# STM32WL5X_CM4 register map
File version: 2.2
CPU: CM4 r0p1, little endian, MPU, no FPU, 4 interrupt priority bits
Registers are 32-bit, read-write, reset 0x0 unless marked. A register's access mark holds for its fields unless they carry their own. Offsets are from the block's base; [hi:lo] are bit positions; {n}, {i} and the like mark numbered series; 'fields as' and 'values as' point back to an identical list.

## IPCC — Inter Processor communication controller
Base 0x58000C00
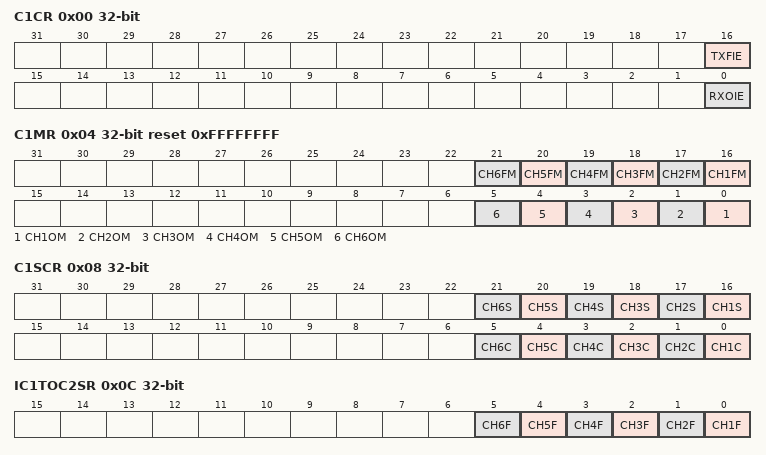
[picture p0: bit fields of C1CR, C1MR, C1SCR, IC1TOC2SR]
0x00 C1CR — IPCC Processor 1 control register
  [16] TXFIE
    0=Disabled (Processor TX free interrupt disabled); 1=Enabled (Enable an unmasked processor transmit channel free to generate a TX free interrupt)
  [0] RXOIE
    0=Disabled (Processor RX occupied interrupt disabled); 1=Enabled (Enable an unmasked processor receive channel occupied to generate an RX occupied interrupt)
0x04 C1MR reset 0xFFFFFFFF — IPCC Processor 1 mask register
  [n+15] CH{n}FM (n=1..6)
    0=Unmasked (Transmit channel n free interrupt not masked); 1=Masked (Transmit channel n free interrupt masked)
  [n-1] CH{n}OM (n=1..6)
    0=Unmasked (Receive channel n occupied interrupt not masked); 1=Masked (Receive channel n occupied interrupt masked)
0x08 C1SCR — Reading this register will always return 0x0000 0000.
  [n+15] CH{n}S (n=1..6)
    0=NoAction; 1=Set (Processor transmit channel n status bit set)
  [n-1] CH{n}C (n=1..6)
    0=NoAction; 1=Clear (Processor receive channel n status bit clear)
0x0C IC1TOC2SR ro — IPCC processor 1 to processor 2 status register
  [n-1] CH{n}F (n=1..6)
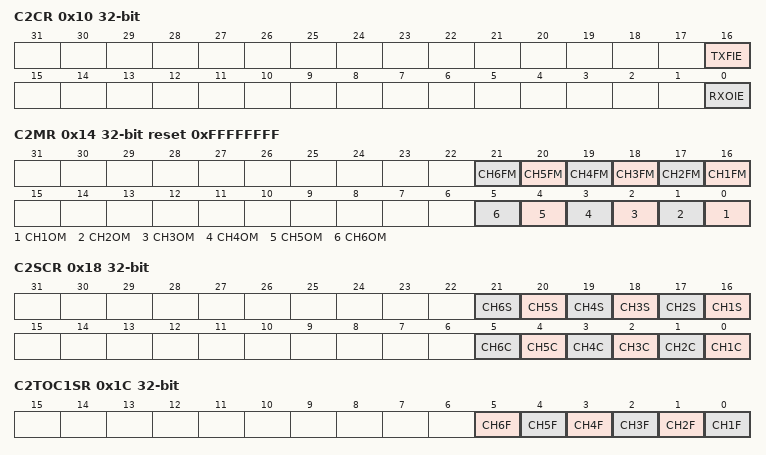
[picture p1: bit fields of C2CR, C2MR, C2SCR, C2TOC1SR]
0x10 C2CR — IPCC Processor 2 control register
  fields as C1CR
0x14 C2MR reset 0xFFFFFFFF — IPCC Processor 2 mask register
  fields as C1MR
0x18 C2SCR — Reading this register will always return 0x0000 0000.
  fields as C1SCR
0x1C C2TOC1SR ro — IPCC processor 2 to processor 1 status register
  [5] CH6F
  [n-1] CH{n}F (n=1..5)
    0=Free (Channel free, data can be written by the sending processor. Generates a channel TX free interrupt to the current processor, when unmasked); 1=Occupied (Channel occupied, data can be read by the receiving processor. Generates a channel RX occupied interrupt to the other processor, when unmasked)
0x3F0 HWCFGR ro reset 0x6 — IPCC Hardware configuration register
  [7:0] CHANNELS
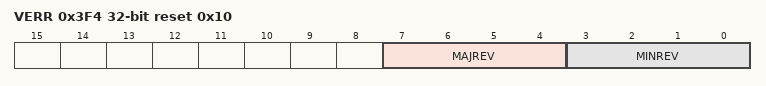
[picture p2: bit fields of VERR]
0x3F4 VERR ro reset 0x10 — IPCC IP Version register
  [7:4] MAJREV, [3:0] MINREV
0x3F8 IPIDR ro reset 0x100071 — IPCC IP Identification register
  [31:0] ID
0x3FC SIDR ro reset 0xA3C5DD01 — IPCC Size ID register
  [31:0] SID

## IWDG — Independent watchdog
Base 0x40003000
0x00 KR 16-bit wo — Key register
  [15:0] KEY — Key value (write only, read 0x0000)
    0x5555=Unlock (Enable access to PR, RLR and WINR registers); 0xAAAA=Feed watchdog with RLR register value; 0xCCCC=Start the watchdog
0x04 PR 16-bit reset 0x7 — Prescaler register
  [2:0] PR — Prescaler divider
    0=DivideBy4 (Divider /4); 1=DivideBy8 (Divider /8); 2=DivideBy16 (Divider /16); 3=DivideBy32 (Divider /32); 4=DivideBy64 (Divider /64); 5=DivideBy128 (Divider /128); other=DivideBy256 (Divider /256)
0x08 RLR 16-bit reset 0xFFF — Reload register
  [11:0] RL — Watchdog counter reload value
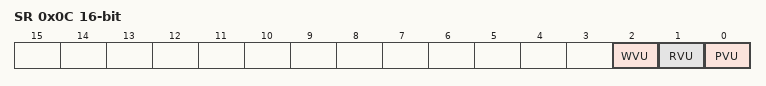
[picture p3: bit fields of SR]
0x0C SR 16-bit ro — Status register
  [all] fields
    0=Idle (No update on-going); 1=Busy (Update on-going)
  [2] WVU — Watchdog counter window value update
  [1] RVU — Watchdog counter reload value update
  [0] PVU — Watchdog prescaler value update

## PKA — Public key accelerator
Base 0x58002000
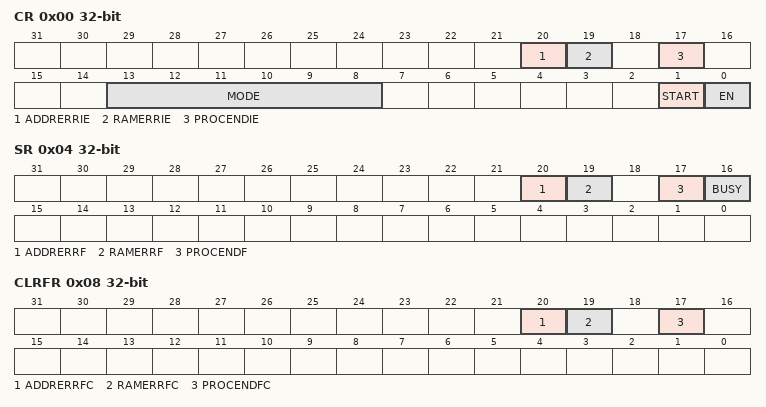
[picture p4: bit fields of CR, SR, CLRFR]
0x00 CR — control register
  [20] ADDRERRIE — Address error interrupt enable
    0=Disabled (No interrupt is generated when ADDRERRF flag is set in PKA_SR); 1=Enabled (An interrupt is generated when ADDRERRF flag is set in PKA_SR)
  [19] RAMERRIE — RAM error interrupt enable
    0=Disabled (No interrupt is generated when RAMERRF flag is set in PKA_SR); 1=Enabled (An interrupt is generated when RAMERRF flag is set in PKA_SR)
  [17] PROCENDIE
    0=Disabled (No interrupt is generated when PROCENDF flag is set in PKA_SR); 1=Enabled (An interrupt is generated when PROCENDF flag is set in PKA_SR)
  [13:8] MODE — PKA operation code
    0=MontgomeryCompExp (Montgomery parameter computation then modular exponentiation); 1=MontgomeryComp (Montgomery parameter computation only); 2=MontgomeryExp (Modular exponentiation only (Montgomery parameter must be loaded first)); 7=RSA (RSA CRT exponentiation); 8=Modular inversion; 9=Arithmetic addition; 10=Arithmetic subtraction; 11=Arithmetic multiplication; 12=Arithmetic comparison; 13=Modular reduction; 14=Modular addition; 15=Modular subtraction; 16=ModularMul (Montgomery multiplication); 32=MontgomeryCompScalar (Montgomery parameter computation then ECC scalar multiplication); 34=MontgomeryScalar (ECC scalar multiplication only (Montgomery parameter must be loaded first)); 36=ECDSASign; 38=ECDSA verification; 40=Elliptic (Point on elliptic curve Fp check)
  [1] START — start the operation
    on write: 1=Start (Writing 1 to this bit starts the operation which is selected by MODE[5:0], using the operands and data already written to the PKA RAM - This bit is always read as 0)
  [0] EN — PKA enable.
    0=Disabled (Disable PKA); 1=Enabled (Enable PKA)
0x04 SR ro — status register
  [20] ADDRERRF — Address error flag
    0=NoError; 1=Error (Address access is out of range (unmapped address))
  [19] RAMERRF — PKA RAM error flag
    0=NoError; 1=Error (An AHB access to the PKA RAM occurred while the PKA core was computing and using its internal RAM (AHB PKA_RAM access are not allowed while PKA operation is in progress))
  [17] PROCENDF — PKA End of Operation flag
    0=InProgress (Operation in progress); 1=Completed (PKA operation is completed - set when BUSY is deasserted)
  [16] BUSY — PKA operation is in progressThis bit is set to 1 whenever START bit in the PKA_CR is set. It is automatically cleared when the computation is complete, meaning that PKA RAM can be safely accessed and a new operation can be started.
    0=Idle (No operation in pgoress); 1=Busy (Operation in progress)
0x08 CLRFR wo — clear flag register
  [20] ADDRERRFC — Clear Address error flag
    1=Clear ADDRERRF flag
  [19] RAMERRFC — Clear PKA RAM error flag
    1=Clear RAMERRF flag
  [17] PROCENDFC — Clear PKA End of Operation flag
    1=Clear PROCENDF flag
